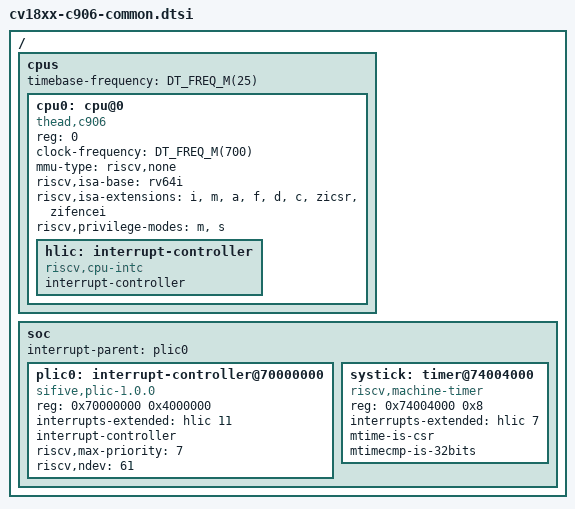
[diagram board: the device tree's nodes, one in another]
/*
 * Copyright (c) 2023-2024 Chen Xingyu <hi@xingrz.me>
 * SPDX-License-Identifier: Apache-2.0
 */

#include <mem.h>
#include <freq.h>

/ {
	cpus {
		#address-cells = <1>;
		#size-cells = <0>;

		timebase-frequency = <DT_FREQ_M(25)>;

		cpu0: cpu@0 {
			compatible = "thead,c906", "riscv";
			reg = <0>;
			clock-frequency = <DT_FREQ_M(700)>;
			mmu-type = "riscv,none";
			riscv,isa-base = "rv64i";
			riscv,isa-extensions = "i", "m", "a", "f", "d", "c", "zicsr", "zifencei";
			riscv,privilege-modes = "m", "s";

			hlic: interrupt-controller {
				compatible = "riscv,cpu-intc";
				#address-cells = <0>;
				#interrupt-cells = <1>;
				interrupt-controller;
			};
		};
	};

	soc {
		#address-cells = <1>;
		#size-cells = <1>;
		interrupt-parent = <&plic0>;

		plic0: interrupt-controller@70000000 {
			compatible = "sifive,plic-1.0.0";
			reg = <0x70000000 0x4000000>;
			interrupts-extended = <&hlic 11>;
			interrupt-controller;
			riscv,max-priority = <7>;
			riscv,ndev = <61>;
			#address-cells = <0>;
			#interrupt-cells = <2>;
		};

		systick: timer@74004000 {
			compatible = "riscv,machine-timer";
			reg = <0x74004000 0x8>;
			reg-names = "mtimecmp";
			interrupts-extended = <&hlic 7>;
			mtime-is-csr;
			mtimecmp-is-32bits;
		};
	};
};
